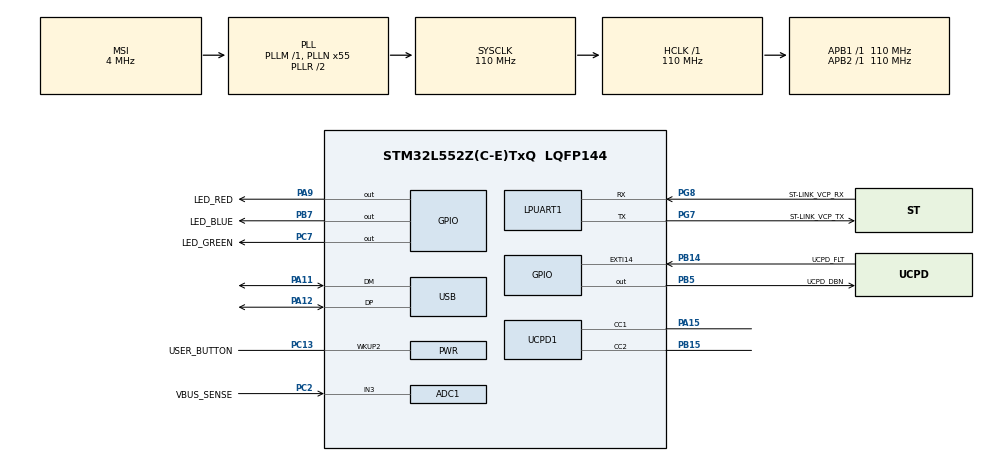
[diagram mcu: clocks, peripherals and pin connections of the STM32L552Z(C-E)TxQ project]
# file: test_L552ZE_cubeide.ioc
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Mcu.Family=STM32L5
PG8.Mode=Asynchronous
RCC.CortexFreq_Value=110000000
PG8.Signal=LPUART1_RX
PB14.GPIO_Label=UCPD_FLT
VP_RTC_VS_RTC_Activate.Mode=RTC_Enabled
PA11.Mode=Device
PA15\ (JTDI).Signal=UCPD1_CC1
PC15-OSC32_OUT\ (PC15).Mode=LSE-External-Oscillator
PC13.GPIO_Label=USER_BUTTON
PB15.Signal=UCPD1_CC2
RCC.SYSCLKSource=RCC_SYSCLKSOURCE_PLLCLK
ProjectManager.StackSize=0x400
PC14-OSC32_IN\ (PC14).Mode=LSE-External-Oscillator
PA14\ (JTCK/SWCLK).Signal=DEBUG_JTCK-SWCLK
PA15\ (JTDI).Mode=Source_AllSignals
PA12.Signal=USB_DP
RCC.ADCCLockSelection=RCC_ADCCLKSOURCE_SYSCLK
RCC.HCLKFreq_Value=110000000
SH.ADCx_IN3.0=ADC1_IN3,IN3-Single-Ended
RCC.APB2TimFreq_Value=110000000
PC7.Signal=GPIO_Output
RCC.AHBFreq_Value=110000000
ADC1.Channel-0\#ChannelRegularConversion=ADC_CHANNEL_3
RCC.HSE_VALUE=8000000
RCC.RTCClockSelection=RCC_RTCCLKSOURCE_LSE
PB7.Signal=GPIO_Output
PA14\ (JTCK/SWCLK).Mode=Trace_Asynchronous_SW
ADC1.SamplingTime-0\#ChannelRegularConversion=ADC_SAMPLETIME_2CYCLES_5
PB7.GPIO_Label=LED_BLUE
Mcu.Package=LQFP144
VP_PWR_VS_DBSignals.Mode=DisableDeadBatterySignals
PB5.GPIO_Label=UCPD_DBN
RCC.APB1TimFreq_Value=110000000
RCC.CK48CLockSelection=RCC_USBCLKSOURCE_HSI48
PC2.GPIO_Label=VBUS_SENSE
RCC.HSI48_VALUE=48000000
RCC.PLLSAI1N=24
RCC.MSI_VALUE=4000000
ADC1.Rank-0\#ChannelRegularConversion=1
PG7.Signal=LPUART1_TX
PA13\ (JTMS/SWDIO).Mode=Trace_Asynchronous_SW
ADC1.OffsetNumber-0\#ChannelRegularConversion=ADC_OFFSET_NONE
PC13.Signal=PWR_WKUP2
PA9.GPIO_Label=LED_RED
PC2.Signal=ADCx_IN3
PC15-OSC32_OUT\ (PC15).Signal=RCC_OSC32_OUT
PG8.GPIO_Label=ST-LINK_VCP_RX
PB3\ (JTDO/TRACESWO).Signal=DEBUG_JTDO-SWO
ProjectManager.TargetToolchain=STM32CubeIDE
PA9.Signal=GPIO_Output
RCC.USBFreq_Value=48000000
PG7.Mode=Asynchronous
PB14.Signal=GPXTI14
board=NUCLEO-L552ZE-Q
RCC.VCOOutputFreq_Value=220000000
PB15.Mode=Source_AllSignals
RCC.APB2Freq_Value=110000000
PG7.GPIO_Label=ST-LINK_VCP_TX
RCC.ADCFreq_Value=110000000
PC13.Mode=WakeUp1
Mcu.Name=STM32L552Z(C-E)TxQ
PC7.GPIO_Label=LED_GREEN
RCC.SYSCLKFreq_VALUE=110000000
PB5.Signal=GPIO_Output
ADC1.master=1
PA12.Mode=Device
Mcu.TrustZone=disable
PC14-OSC32_IN\ (PC14).Signal=RCC_OSC32_IN
PA11.Signal=USB_DM
ProjectManager.HeapSize=0x200
RCC.HSI_VALUE=16000000
NVIC.PriorityGroup=NVIC_PRIORITYGROUP_3
ADC1.NbrOfConversionFlag=1
RCC.PLLN=55
PB3\ (JTDO/TRACESWO).Mode=Trace_Asynchronous_SW
RCC.APB1Freq_Value=110000000
PA13\ (JTMS/SWDIO).Signal=DEBUG_JTMS-SWDIO

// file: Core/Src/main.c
/* USER CODE BEGIN Header */
/**
  ******************************************************************************
  * @file           : main.c
  * @brief          : Main program body
  ******************************************************************************
  * @attention
  *
  * <h2><center>&copy; Copyright (c) 2021 STMicroelectronics.
  * All rights reserved.</center></h2>
  *
  * This software component is licensed by ST under BSD 3-Clause license,
  * the "License"; You may not use this file except in compliance with the
  * License. You may obtain a copy of the License at:
  *                        opensource.org/licenses/BSD-3-Clause
  *
  ******************************************************************************
  */
/* USER CODE END Header */
#include "main.h"
#include "adc.h"
#include "usart.h"
#include "rtc.h"
#include "ucpd.h"
#include "usb.h"
#include "gpio.h"

/* USER CODE BEGIN Includes */
#include <stdio.h>
/* USER CODE END Includes */

void SystemClock_Config(void);

int main(void)
{

  /* MCU Configuration--------------------------------------------------------*/

  /* Reset of all peripherals, Initializes the Flash interface and the Systick. */
  HAL_Init();

  /* Configure the system clock */
  SystemClock_Config();

  /* Initialize all configured peripherals */
  MX_GPIO_Init();
  MX_ADC1_Init();
  MX_LPUART1_UART_Init();
  MX_RTC_Init();
  MX_UCPD1_Init();
  MX_USB_PCD_Init();

  /* Infinite loop */
  /* USER CODE BEGIN WHILE */
  while (1)
  {
	  printf("hello world\n");
	  HAL_Delay(1000);
    /* USER CODE END WHILE */

  }
}

void SystemClock_Config(void)
{
  RCC_OscInitTypeDef RCC_OscInitStruct = {0};
  RCC_ClkInitTypeDef RCC_ClkInitStruct = {0};

  /** Configure the main internal regulator output voltage
  */
  if (HAL_PWREx_ControlVoltageScaling(PWR_REGULATOR_VOLTAGE_SCALE0) != HAL_OK)
  {
    Error_Handler();
  }
  /** Configure LSE Drive Capability
  */
  HAL_PWR_EnableBkUpAccess();
  __HAL_RCC_LSEDRIVE_CONFIG(RCC_LSEDRIVE_LOW);
  /** Initializes the RCC Oscillators according to the specified parameters
  * in the RCC_OscInitTypeDef structure.
  */
  RCC_OscInitStruct.OscillatorType = RCC_OSCILLATORTYPE_HSI48|RCC_OSCILLATORTYPE_LSE
                              |RCC_OSCILLATORTYPE_MSI;
  RCC_OscInitStruct.LSEState = RCC_LSE_ON;
  RCC_OscInitStruct.HSI48State = RCC_HSI48_ON;
  RCC_OscInitStruct.MSIState = RCC_MSI_ON;
  RCC_OscInitStruct.MSICalibrationValue = RCC_MSICALIBRATION_DEFAULT;
  RCC_OscInitStruct.MSIClockRange = RCC_MSIRANGE_6;
  RCC_OscInitStruct.PLL.PLLState = RCC_PLL_ON;
  RCC_OscInitStruct.PLL.PLLSource = RCC_PLLSOURCE_MSI;
  RCC_OscInitStruct.PLL.PLLM = 1;
  RCC_OscInitStruct.PLL.PLLN = 55;
  RCC_OscInitStruct.PLL.PLLP = RCC_PLLP_DIV7;
  RCC_OscInitStruct.PLL.PLLQ = RCC_PLLQ_DIV2;
  RCC_OscInitStruct.PLL.PLLR = RCC_PLLR_DIV2;
  if (HAL_RCC_OscConfig(&RCC_OscInitStruct) != HAL_OK)
  {
    Error_Handler();
  }
  /** Initializes the CPU, AHB and APB buses clocks
  */
  RCC_ClkInitStruct.ClockType = RCC_CLOCKTYPE_HCLK|RCC_CLOCKTYPE_SYSCLK
                              |RCC_CLOCKTYPE_PCLK1|RCC_CLOCKTYPE_PCLK2;
  RCC_ClkInitStruct.SYSCLKSource = RCC_SYSCLKSOURCE_PLLCLK;
  RCC_ClkInitStruct.AHBCLKDivider = RCC_SYSCLK_DIV1;
  RCC_ClkInitStruct.APB1CLKDivider = RCC_HCLK_DIV1;
  RCC_ClkInitStruct.APB2CLKDivider = RCC_HCLK_DIV1;

  if (HAL_RCC_ClockConfig(&RCC_ClkInitStruct, FLASH_LATENCY_5) != HAL_OK)
  {
    Error_Handler();
  }
}

/* USER CODE BEGIN 4 */
int _write(int file, char *ptr, int len)
{
  HAL_UART_Transmit(&hlpuart1, (uint8_t *)ptr, 1, 0xFFFF);
  return 1;
}
/* USER CODE END 4 */

void Error_Handler(void)
{
  __disable_irq();
  while (1)
  {
  }
}

/************************ (C) COPYRIGHT STMicroelectronics *****END OF FILE****/
